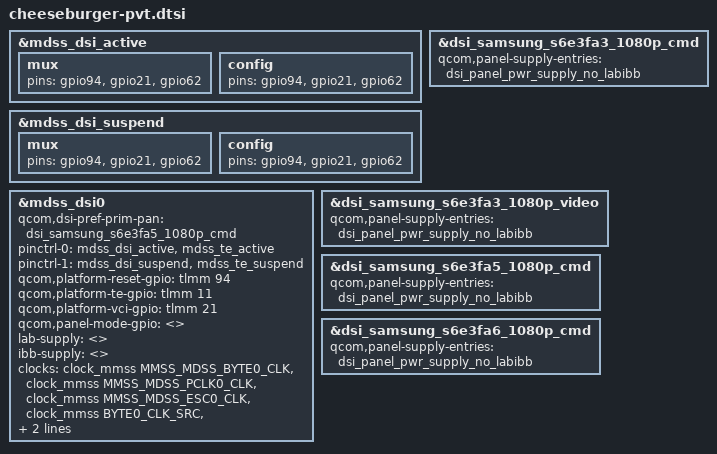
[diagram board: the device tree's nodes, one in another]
/* Copyright (c) 2015-2016, The Linux Foundation. All rights reserved.
 * Copyright (c) 2023, Edrick Vince Sinsuan <sedrickvince@gmail.com>
 *
 * This program is free software; you can redistribute it and/or modify
 * it under the terms of the GNU General Public License version 2 and
 * only version 2 as published by the Free Software Foundation.
 *
 * This program is distributed in the hope that it will be useful,
 * but WITHOUT ANY WARRANTY; without even the implied warranty of
 * MERCHANTABILITY or FITNESS FOR A PARTICULAR PURPOSE.  See the
 * GNU General Public License for more details.
 */

#include "dsi-panel-samsung_s6e3fa3_1080p_cmd.dtsi"
#include "dsi-panel-samsung_s6e3fa3_1080p_video.dtsi"
#include "dsi-panel-samsung_s6e3fa5_1080p_cmd.dtsi"
#include "dsi-panel-samsung_s6e3fa6_1080p_cmd.dtsi"

&mdss_dsi_active {
	mux {
		pins = "gpio94", "gpio21", "gpio62";
	};
	config {
		pins = "gpio94", "gpio21", "gpio62";
	};
};

&mdss_dsi_suspend {
	mux {
		pins = "gpio94", "gpio21", "gpio62";
	};
	config {
		pins = "gpio94", "gpio21", "gpio62";
	};
};

&mdss_dsi0 {
	qcom,dsi-pref-prim-pan = <&dsi_samsung_s6e3fa5_1080p_cmd>;
	pinctrl-names = "mdss_default", "mdss_sleep";
	pinctrl-0 = <&mdss_dsi_active &mdss_te_active>;
	pinctrl-1 = <&mdss_dsi_suspend &mdss_te_suspend>;
	qcom,platform-reset-gpio = <&tlmm 94 0>;
	qcom,platform-te-gpio = <&tlmm 11 0>;
	qcom,platform-vci-gpio = <&tlmm 21 0>;
	qcom,panel-mode-gpio = <>;
	lab-supply = <>;
	ibb-supply = <>;
	clocks = <&clock_mmss MMSS_MDSS_BYTE0_CLK>,
		 <&clock_mmss MMSS_MDSS_PCLK0_CLK>,
		 <&clock_mmss MMSS_MDSS_ESC0_CLK>,
		 <&clock_mmss BYTE0_CLK_SRC>,
		 <&clock_mmss PCLK0_CLK_SRC>,
		 <&clock_mmss MMSS_MDSS_BYTE0_INTF_CLK>;
	clock-names = "byte_clk", "pixel_clk", "core_clk",
		"byte_clk_rcg", "pixel_clk_rcg",
		"byte_intf_clk";
};

&dsi_samsung_s6e3fa3_1080p_cmd {
	qcom,panel-supply-entries = <&dsi_panel_pwr_supply_no_labibb>;
};

&dsi_samsung_s6e3fa3_1080p_video {
	qcom,panel-supply-entries = <&dsi_panel_pwr_supply_no_labibb>;
};

&dsi_samsung_s6e3fa5_1080p_cmd {
	qcom,panel-supply-entries = <&dsi_panel_pwr_supply_no_labibb>;
};

&dsi_samsung_s6e3fa6_1080p_cmd {
	qcom,panel-supply-entries = <&dsi_panel_pwr_supply_no_labibb>;
};

#include "msm8998-oneplus-common-pvt.dtsi"
